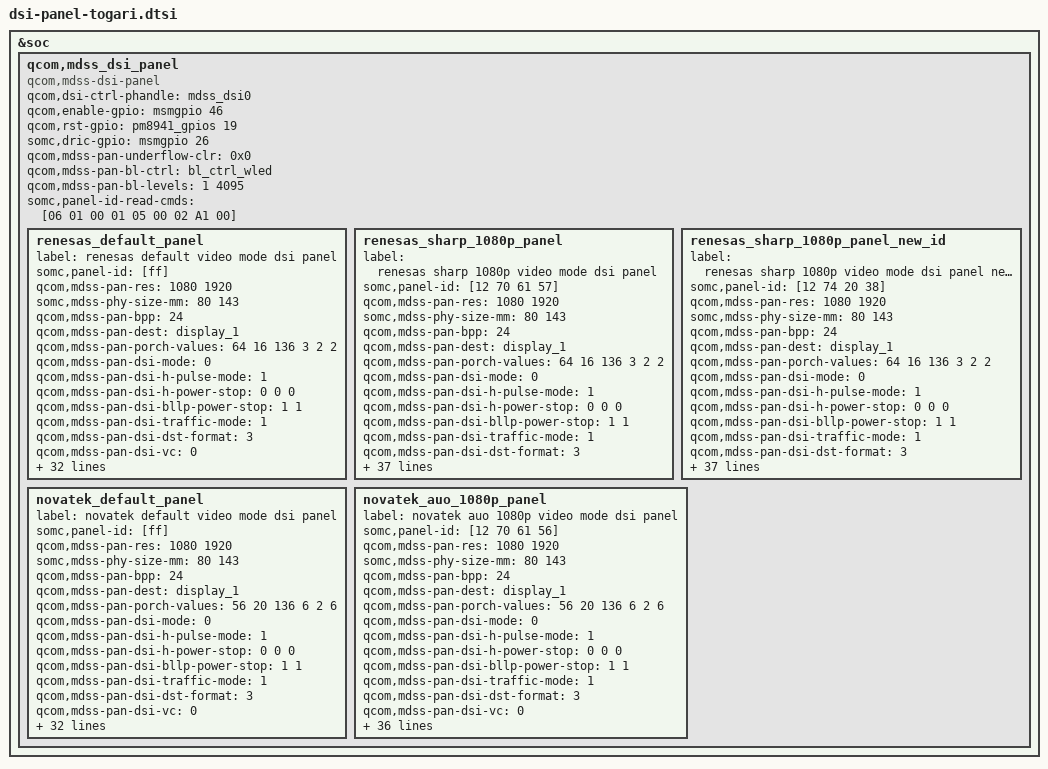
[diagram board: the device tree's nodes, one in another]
/* Copyright (c) 2012, Code Aurora Forum. All rights reserved.
 * Copyright (C) 2012-2013 Sony Mobile Communications AB.
 *
 * This program is free software; you can redistribute it and/or modify
 * it under the terms of the GNU General Public License version 2 and
 * only version 2 as published by the Free Software Foundation.
 *
 * This program is distributed in the hope that it will be useful,
 * but WITHOUT ANY WARRANTY; without even the implied warranty of
 * MERCHANTABILITY or FITNESS FOR A PARTICULAR PURPOSE.  See the
 * GNU General Public License for more details.
 */

&soc {

	qcom,mdss_dsi_panel {
		/* common */
		compatible = "qcom,mdss-dsi-panel";
		status = "ok";
		qcom,dsi-ctrl-phandle = <&mdss_dsi0>;
		qcom,enable-gpio = <&msmgpio 46 0>;
		qcom,rst-gpio = <&pm8941_gpios 19 0>;
		somc,dric-gpio = <&msmgpio 26 0>;
		qcom,mdss-pan-underflow-clr = <0x0>;
		qcom,mdss-pan-bl-ctrl = "bl_ctrl_wled";
		qcom,mdss-pan-bl-levels = <1 4095>;
		somc,panel-id-read-cmds = [06 01 00 01 05 00 02 A1 00];

		renesas_default_panel {
			label = "renesas default video mode dsi panel";
			somc,panel-id = [ff];
			qcom,mdss-pan-res = <1080 1920>;
			somc,mdss-phy-size-mm = <80 143>;
			qcom,mdss-pan-bpp = <24>;
			qcom,mdss-pan-dest = "display_1";
			qcom,mdss-pan-porch-values = <64 16 136 3 2 2>;
			qcom,mdss-pan-dsi-mode = <0>;
			qcom,mdss-pan-dsi-h-pulse-mode = <1>;
			qcom,mdss-pan-dsi-h-power-stop = <0 0 0>;
			qcom,mdss-pan-dsi-bllp-power-stop = <1 1>;
			qcom,mdss-pan-dsi-traffic-mode = <1>;
			qcom,mdss-pan-dsi-dst-format = <3>;
			qcom,mdss-pan-dsi-vc = <0>;
			qcom,mdss-pan-dsi-rgb-swap = <0>;
			qcom,mdss-pan-dsi-data-lanes = <1 1 1 1>;
			qcom,mdss-pan-dsi-dlane-swap = <0>;
			qcom,mdss-pan-dsi-t-clk = <0x31 0x03>;
			qcom,mdss-pan-dsi-stream = <0>;
			qcom,mdss-pan-dsi-mdp-tr = <0x0>;
			qcom,mdss-pan-dsi-dma-tr = <0x04>;
			qcom,mdss-pan-dsi-frame-rate = <60>;
			qcom,panel-phy-regulatorSettings = [07 09 03 00  /* Regualotor settings */
							    20 00 01];
			qcom,panel-phy-timingSettings = [EA 38 25 00 67 6F
							    29 3C 5D 03 04 00];
			qcom,panel-phy-strengthCtrl = [ff 06];
			qcom,panel-phy-bistCtrl = [00 00 b1 ff           /* BIST Ctrl settings */
						   00 00];
			qcom,panel-phy-laneConfig = [00 c2 ef 00 00 00 00 01 75 /* lane0 config */
						00 c2 ef 00 00 00 00 01 75 /* lane1 config */
						00 c2 ef 00 00 00 00 01 75 /* lane2 config */
						00 c2 ef 00 00 00 00 01 75 /* lane3 config */
						00 02 45 00 00 00 00 01 97]; /* Clk ln config */

			somc,panel-cabc-early-on-cmds = [39 01 00 00 00 00 03 51 0F FF
							15 01 00 00 00 00 02 53 24
							15 01 00 00 00 00 02 55 03
							23 01 00 00 00 00 02 B0 00
							29 01 00 00 00 00 08 B9 00 3F 18 18 9F 1F 80
							29 01 00 00 00 00 08 BA 00 3F 04 40 9F 1F A8
							29 01 00 00 00 00 0B B8 18 80 18 18 CF 1F 00 0C 0F 6C
							29 01 00 00 00 00 0F 0F 6C 0F 0C 0F DA 6D FF FF 10 7D BC F7 FF FF
							23 01 00 00 00 00 02 B0 03];
			somc,panel-cabc-late-off-cmds = [39 01 00 00 00 00 03 51 00 00
							15 01 00 00 00 00 02 55 00
							15 01 00 00 00 00 02 53 20];
			somc,cabc-enabled = <1>;
			somc,panel-init-cmds = [29 01 00 00 00 00 02 B0 04
				05 01 00 00 00 00 02 00 00
				05 01 00 00 00 00 02 00 00
				29 01 00 00 00 00 07 B3 14 00 00 00 00 00
				29 01 00 00 00 00 03 B4 0C 00
				29 01 00 00 00 00 03 B6 3A D3
				29 01 00 00 00 00 02 B7 00
				29 01 00 00 00 00 03 BB 00 10
				29 01 00 00 00 00 03 C0 00 00
				29 01 00 00 00 00 23 C1
					04 60 00 40 0C 00 50 02 00 00 00 5C 63 AC 39 00
					00 50 00 00 00 86 00 00 00 00 00 00 40 00 02 02
					02 00
				29 01 00 00 00 00 08 C2 30 17 80 05 08 00 00
				29 01 00 00 00 00 04 C3 00 00 00
				29 01 00 00 00 00 17 C4
					70 00 00 00 00 00 00 00 00 00 06 00 00 00 00 00
					00 00 00 00 00 06
				29 01 00 00 00 00 29 C6
					01 6E 02 67 00 00 00 00 00 00 00 00 00 00 00 00
					04 19 0A 03 C7 01 6E 02 67 00 00 00 00 00 00 00
					00 00 00 00 00 04 19 0A
				29 01 00 00 00 00 19 C7
					0F 14 17 1B 22 42 36 51 62 6B 6E 6E 11 15 19 1D
					24 3F 34 53 65 6D 6F 71
				29 01 00 00 00 00 19 C8
					0F 14 18 1E 29 42 35 50 62 6B 71 73 11 16 1A 20
					2B 40 33 52 64 6C 72 76
				29 01 00 00 00 00 19 C9
					13 17 1B 20 2B 42 35 52 63 6B 6F 6F 15 19 1D 22
					2C 40 34 53 64 6C 70 72
				29 01 00 00 00 00 21 CA
					00 80 80 80 80 80 80 80 08 20 80 80 0A 4A 37 A0
					55 F8 0C 0C 20 10 3F 3F 00 00 10 10 3F 3F 3F 3F
				29 01 00 00 00 00 0A CB 66 E0 87 61 00 00 00 00 C0
				29 01 00 00 00 00 02 CC 03
				29 01 00 00 00 00 08 CE 00 01 00 C1 00 00 00
				29 01 00 00 00 00 06 CF 00 00 C1 05 3F
				29 01 00 00 00 00 0F D0 00 00 19 18 99 9C 1C 01 81 00 BB 1B 0B 01
				29 01 00 00 00 00 1E D1
					20 00 00 04 08 0C 10 00 00 00 00 00 3C 04 20 00
					00 04 08 0C 10 00 00 3C 06 40 00 32 31
				29 01 00 00 00 00 04 D2 5C 00 00
				29 01 00 00 00 00 1B D3
					1B 33 BB CC C4 33 33 33 00 01 00 A0 F8 A0 00 3F
					33 33 22 70 02 37 03 3D BF 99
				29 01 00 00 00 00 15 D7
					84 E0 7F A8 CE 38 FC C1 83 E7 83 1F 3C 10 FA C3
					0F 04 41 20
				29 01 00 00 00 00 07 D8 00 80 80 40 42 21
				29 01 00 00 00 00 03 D9 20 00
				29 01 00 00 00 00 03 DD 10 8C
				29 01 00 00 00 00 07 DE 00 FF 07 10 00 77
				29 01 00 00 00 00 03 EC 40 10
				29 01 00 00 00 00 04 ED 00 00 00
				29 01 00 00 00 00 03 EE 00 32
				29 01 00 00 00 00 0D EF 00 00 00 00 00 00 00 00 00 00 00 00
				29 01 00 00 00 00 02 D6 01
				05 01 00 00 00 00 01 11];
			qcom,panel-on-cmds = [05 01 00 00 00 00 01 29];

			qcom,on-cmds-dsi-state = "DSI_LP_MODE";
			qcom,panel-off-cmds = [05 01 00 00 14 00 01 28
					05 01 00 00 64 00 01 10];
			qcom,off-cmds-dsi-state = "DSI_HS_MODE";
			somc,driver-ic = <0>;
			somc,disp-on-in-hs = <1>;
			somc,panel-detect = <1>;
			somc,wait-time-before-on-cmd = <150>;
		};

		renesas_sharp_1080p_panel {
			label = "renesas sharp 1080p video mode dsi panel";
			somc,panel-id = [12 70 61 57];
			qcom,mdss-pan-res = <1080 1920>;
			somc,mdss-phy-size-mm = <80 143>;
			qcom,mdss-pan-bpp = <24>;
			qcom,mdss-pan-dest = "display_1";
			qcom,mdss-pan-porch-values = <64 16 136 3 2 2>;
			qcom,mdss-pan-dsi-mode = <0>;
			qcom,mdss-pan-dsi-h-pulse-mode = <1>;
			qcom,mdss-pan-dsi-h-power-stop = <0 0 0>;
			qcom,mdss-pan-dsi-bllp-power-stop = <1 1>;
			qcom,mdss-pan-dsi-traffic-mode = <1>;
			qcom,mdss-pan-dsi-dst-format = <3>;
			qcom,mdss-pan-dsi-vc = <0>;
			qcom,mdss-pan-dsi-rgb-swap = <0>;
			qcom,mdss-pan-dsi-data-lanes = <1 1 1 1>;
			qcom,mdss-pan-dsi-dlane-swap = <0>;
			qcom,mdss-pan-dsi-t-clk = <0x31 0x03>;
			qcom,mdss-pan-dsi-stream = <0>;
			qcom,mdss-pan-dsi-mdp-tr = <0x0>;
			qcom,mdss-pan-dsi-dma-tr = <0x04>;
			qcom,mdss-pan-dsi-frame-rate = <60>;
			qcom,panel-phy-regulatorSettings = [07 09 03 00  /* Regualotor settings */
							    20 00 01];
			qcom,panel-phy-timingSettings = [EA 38 25 00 67 6F
							    29 3C 5D 03 04 00];
			qcom,panel-phy-strengthCtrl = [ff 06];
			qcom,panel-phy-bistCtrl = [00 00 b1 ff           /* BIST Ctrl settings */
						   00 00];
			qcom,panel-phy-laneConfig = [00 c2 ef 00 00 00 00 01 75 /* lane0 config */
						00 c2 ef 00 00 00 00 01 75 /* lane1 config */
						00 c2 ef 00 00 00 00 01 75 /* lane2 config */
						00 c2 ef 00 00 00 00 01 75 /* lane3 config */
						00 02 45 00 00 00 00 01 97]; /* Clk ln config */

			somc,panel-cabc-early-on-cmds = [39 01 00 00 00 00 03 51 0F FF
							15 01 00 00 00 00 02 53 24
							15 01 00 00 00 00 02 55 03
							23 01 00 00 00 00 02 B0 00
							29 01 00 00 00 00 08 B9 00 3F 18 18 9F 1F 80
							29 01 00 00 00 00 08 BA 00 3F 04 40 9F 1F A8
							29 01 00 00 00 00 0B B8 18 80 18 18 CF 1F 00 0C 0F 6C
							29 01 00 00 00 00 0F 0F 6C 0F 0C 0F DA 6D FF FF 10 7D BC F7 FF FF
							23 01 00 00 00 00 02 B0 03];
			somc,panel-cabc-late-off-cmds = [39 01 00 00 00 00 03 51 00 00
							15 01 00 00 00 00 02 55 00
							15 01 00 00 00 00 02 53 20];
			somc,cabc-enabled = <1>;

			somc,panel-init-cmds = [29 01 00 00 00 00 02 B0 04
				05 01 00 00 00 00 02 00 00
				05 01 00 00 00 00 02 00 00
				29 01 00 00 00 00 07 B3 14 00 00 00 00 00
				29 01 00 00 00 00 03 B4 0C 00
				29 01 00 00 00 00 03 B6 3A D3
				29 01 00 00 00 00 02 B7 00
				29 01 00 00 00 00 03 BB 00 10
				29 01 00 00 00 00 03 C0 00 00
				29 01 00 00 00 00 23 C1
					04 60 00 40 0C 00 50 02 00 00 00 5C 63 AC 39 00
					00 50 00 00 00 86 00 00 00 00 00 00 40 00 02 02
					02 00
				29 01 00 00 00 00 08 C2 30 17 80 05 08 00 00
				29 01 00 00 00 00 04 C3 00 00 00
				29 01 00 00 00 00 17 C4
					70 00 00 00 00 00 00 00 00 00 06 00 00 00 00 00
					00 00 00 00 00 06
				29 01 00 00 00 00 29 C6
					01 6E 02 67 00 00 00 00 00 00 00 00 00 00 00 00
					04 19 0A 03 C7 01 6E 02 67 00 00 00 00 00 00 00
					00 00 00 00 00 04 19 0A
				29 01 00 00 00 00 19 C7
					0F 14 17 1B 22 42 36 51 62 6B 6E 6E 11 15 19 1D
					24 3F 34 53 65 6D 6F 71
				29 01 00 00 00 00 19 C8
					0F 14 18 1E 29 42 35 50 62 6B 71 73 11 16 1A 20
					2B 40 33 52 64 6C 72 76
				29 01 00 00 00 00 19 C9
					13 17 1B 20 2B 42 35 52 63 6B 6F 6F 15 19 1D 22
					2C 40 34 53 64 6C 70 72
				29 01 00 00 00 00 21 CA
					00 80 80 80 80 80 80 80 08 20 80 80 0A 4A 37 A0
					55 F8 0C 0C 20 10 3F 3F 00 00 10 10 3F 3F 3F 3F
				29 01 00 00 00 00 0A CB 66 E0 87 61 00 00 00 00 C0
				29 01 00 00 00 00 02 CC 03
				29 01 00 00 00 00 08 CE 00 01 00 C1 00 00 00
				29 01 00 00 00 00 06 CF 00 00 C1 05 3F
				29 01 00 00 00 00 0F D0 00 00 19 18 99 9C 1C 01 81 00 BB 1B 0B 01
				29 01 00 00 00 00 1E D1
					20 00 00 04 08 0C 10 00 00 00 00 00 3C 04 20 00
					00 04 08 0C 10 00 00 3C 06 40 00 32 31
				29 01 00 00 00 00 04 D2 5C 00 00
				29 01 00 00 00 00 1B D3
					1B 33 BB CC C4 33 33 33 00 01 00 A0 F8 A0 00 3F
					33 33 22 70 02 37 03 3D BF 99
				29 01 00 00 00 00 15 D7
					84 E0 7F A8 CE 38 FC C1 83 E7 83 1F 3C 10 FA C3
					0F 04 41 20
				29 01 00 00 00 00 07 D8 00 80 80 40 42 21
				29 01 00 00 00 00 03 D9 20 00
				29 01 00 00 00 00 03 DD 10 8C
				29 01 00 00 00 00 07 DE 00 FF 07 10 00 77
				29 01 00 00 00 00 03 EC 40 10
				29 01 00 00 00 00 04 ED 00 00 00
				29 01 00 00 00 00 03 EE 00 32
				29 01 00 00 00 00 0D EF 00 00 00 00 00 00 00 00 00 00 00 00
				29 01 00 00 00 00 02 D6 01
				05 01 00 00 00 00 01 11];
			qcom,panel-on-cmds = [05 01 00 00 00 00 01 29];

			qcom,on-cmds-dsi-state = "DSI_LP_MODE";
			qcom,panel-off-cmds = [05 01 00 00 14 00 01 28
					05 01 00 00 64 00 01 10];
			qcom,off-cmds-dsi-state = "DSI_HS_MODE";
			somc,driver-ic = <0>;
			somc,disp-on-in-hs = <1>;
			somc,wait-time-before-on-cmd = <150>;

			somc,panel-uv-cmds = [04 01 00 00 00 00 01 EF];
			somc,panel-pcc-table = <0x07c00 0x05f80 0x07380	/* CLR01_GRN */
					0x05100 0x06600 0x07380		/* CLR02_YEL */
					0x07d80 0x05f80 0x06300		/* CLR03_LB */
					0x04e00 0x06600 0x06100		/* CLR04_ORG */
					0x07d00 0x05f00 0x05680		/* CLR05_BLE */
					0x07d80 0x08000 0x06f80		/* CLR06_PUR */
					0x04d00 0x06600 0x05280>;	/* CLR07_RED */
			somc,panel-pcc-sub-table = <0x06800 0x06f80 0x08000 /* Area01 (R G B) */
					0x06500 0x07100 0x08000
					0x07600 0x07400 0x08000
					0x07480 0x07580 0x08000
					0x07280 0x07500 0x08000
					0x06d80 0x07500 0x08000
					0x06780 0x07300 0x08000
					0x07a00 0x07680 0x08000
					0x07900 0x07800 0x08000
					0x07180 0x07800 0x08000
					0x06f00 0x07880 0x08000
					0x06c00 0x07800 0x08000
					0x07d80 0x07980 0x08000
					0x07b80 0x07b00 0x08000
					0x07600 0x07d00 0x08000
					0x07180 0x07b00 0x08000
					0x07000 0x07d00 0x08000
					0x08000 0x07980 0x07d00
					0x07f00 0x07b00 0x07d80
					0x07c00 0x07c00 0x07c80
					0x07100 0x07b00 0x07d00
					0x07280 0x07d00 0x07e80
					0x07000 0x07d00 0x07e80
					0x08000 0x07800 0x07900
					0x08000 0x07c00 0x07c00
					0x07a80 0x08000 0x07e80
					0x07680 0x08000 0x07d80
					0x07300 0x08000 0x07f00
					0x08000 0x07800 0x07580
					0x08000 0x07b00 0x07780
					0x08000 0x08000 0x07c80
					0x07900 0x08000 0x07980
					0x08000 0x07880 0x07480
					0x08000 0x07c00 0x07600
					0x07d80 0x08000 0x07880
					0x07300 0x08000 0x07780
					0x08000 0x07400 0x07c80
					0x07880 0x06e00 0x08000
					0x06b80 0x06b00 0x07e00
					0x06080 0x05f80 0x07780
					0x05880 0x06500 0x07c80
					0x05500 0x06600 0x05e80>;
		};

		renesas_sharp_1080p_panel_new_id {
			label = "renesas sharp 1080p video mode dsi panel new id";
			somc,panel-id = [12 74 20 38];
			qcom,mdss-pan-res = <1080 1920>;
			somc,mdss-phy-size-mm = <80 143>;
			qcom,mdss-pan-bpp = <24>;
			qcom,mdss-pan-dest = "display_1";
			qcom,mdss-pan-porch-values = <64 16 136 3 2 2>;
			qcom,mdss-pan-dsi-mode = <0>;
			qcom,mdss-pan-dsi-h-pulse-mode = <1>;
			qcom,mdss-pan-dsi-h-power-stop = <0 0 0>;
			qcom,mdss-pan-dsi-bllp-power-stop = <1 1>;
			qcom,mdss-pan-dsi-traffic-mode = <1>;
			qcom,mdss-pan-dsi-dst-format = <3>;
			qcom,mdss-pan-dsi-vc = <0>;
			qcom,mdss-pan-dsi-rgb-swap = <0>;
			qcom,mdss-pan-dsi-data-lanes = <1 1 1 1>;
			qcom,mdss-pan-dsi-dlane-swap = <0>;
			qcom,mdss-pan-dsi-t-clk = <0x31 0x03>;
			qcom,mdss-pan-dsi-stream = <0>;
			qcom,mdss-pan-dsi-mdp-tr = <0x0>;
			qcom,mdss-pan-dsi-dma-tr = <0x04>;
			qcom,mdss-pan-dsi-frame-rate = <60>;
			qcom,panel-phy-regulatorSettings = [07 09 03 00  /* Regualotor settings */
							    20 00 01];
			qcom,panel-phy-timingSettings = [EA 38 25 00 67 6F
							    29 3C 5D 03 04 00];
			qcom,panel-phy-strengthCtrl = [ff 06];
			qcom,panel-phy-bistCtrl = [00 00 b1 ff           /* BIST Ctrl settings */
						   00 00];
			qcom,panel-phy-laneConfig = [00 c2 ef 00 00 00 00 01 75 /* lane0 config */
						00 c2 ef 00 00 00 00 01 75 /* lane1 config */
						00 c2 ef 00 00 00 00 01 75 /* lane2 config */
						00 c2 ef 00 00 00 00 01 75 /* lane3 config */
						00 02 45 00 00 00 00 01 97]; /* Clk ln config */

			somc,panel-cabc-early-on-cmds = [39 01 00 00 00 00 03 51 0F FF
							15 01 00 00 00 00 02 53 24
							15 01 00 00 00 00 02 55 03
							23 01 00 00 00 00 02 B0 00
							29 01 00 00 00 00 08 B9 00 3F 18 18 9F 1F 80
							29 01 00 00 00 00 08 BA 00 3F 04 40 9F 1F A8
							29 01 00 00 00 00 0B B8 18 80 18 18 CF 1F 00 0C 0F 6C
							29 01 00 00 00 00 0F 0F 6C 0F 0C 0F DA 6D FF FF 10 7D BC F7 FF FF
							23 01 00 00 00 00 02 B0 03];
			somc,panel-cabc-late-off-cmds = [39 01 00 00 00 00 03 51 00 00
							15 01 00 00 00 00 02 55 00
							15 01 00 00 00 00 02 53 20];
			somc,cabc-enabled = <1>;

			somc,panel-init-cmds = [29 01 00 00 00 00 02 B0 04
				05 01 00 00 00 00 02 00 00
				05 01 00 00 00 00 02 00 00
				29 01 00 00 00 00 07 B3 14 00 00 00 00 00
				29 01 00 00 00 00 03 B4 0C 00
				29 01 00 00 00 00 03 B6 3A D3
				29 01 00 00 00 00 02 B7 00
				29 01 00 00 00 00 03 BB 00 10
				29 01 00 00 00 00 03 C0 00 00
				29 01 00 00 00 00 23 C1
					04 60 00 40 0C 00 50 02 00 00 00 5C 63 AC 39 00
					00 50 00 00 00 86 00 00 00 00 00 00 40 00 02 02
					02 00
				29 01 00 00 00 00 08 C2 30 17 80 05 08 00 00
				29 01 00 00 00 00 04 C3 00 00 00
				29 01 00 00 00 00 17 C4
					70 00 00 00 00 00 00 00 00 00 06 00 00 00 00 00
					00 00 00 00 00 06
				29 01 00 00 00 00 29 C6
					01 6E 02 67 00 00 00 00 00 00 00 00 00 00 00 00
					04 19 0A 03 C7 01 6E 02 67 00 00 00 00 00 00 00
					00 00 00 00 00 04 19 0A
				29 01 00 00 00 00 19 C7
					0F 14 17 1B 22 42 36 51 62 6B 6E 6E 11 15 19 1D
					24 3F 34 53 65 6D 6F 71
				29 01 00 00 00 00 19 C8
					0F 14 18 1E 29 42 35 50 62 6B 71 73 11 16 1A 20
					2B 40 33 52 64 6C 72 76
				29 01 00 00 00 00 19 C9
					13 17 1B 20 2B 42 35 52 63 6B 6F 6F 15 19 1D 22
					2C 40 34 53 64 6C 70 72
				29 01 00 00 00 00 21 CA
					00 80 80 80 80 80 80 80 08 20 80 80 0A 4A 37 A0
					55 F8 0C 0C 20 10 3F 3F 00 00 10 10 3F 3F 3F 3F
				29 01 00 00 00 00 0A CB 66 E0 87 61 00 00 00 00 C0
				29 01 00 00 00 00 02 CC 03
				29 01 00 00 00 00 08 CE 00 01 00 C1 00 00 00
				29 01 00 00 00 00 06 CF 00 00 C1 05 3F
				29 01 00 00 00 00 0F D0 00 00 19 18 99 9C 1C 01 81 00 BB 1B 0B 01
				29 01 00 00 00 00 1E D1
					20 00 00 04 08 0C 10 00 00 00 00 00 3C 04 20 00
					00 04 08 0C 10 00 00 3C 06 40 00 32 31
				29 01 00 00 00 00 04 D2 5C 00 00
				29 01 00 00 00 00 1B D3
					1B 33 BB CC C4 33 33 33 00 01 00 A0 F8 A0 00 3F
					33 33 22 70 02 37 03 3D BF 99
				29 01 00 00 00 00 15 D7
					84 E0 7F A8 CE 38 FC C1 83 E7 83 1F 3C 10 FA C3
					0F 04 41 20
				29 01 00 00 00 00 07 D8 00 80 80 40 42 21
				29 01 00 00 00 00 03 D9 20 00
				29 01 00 00 00 00 03 DD 10 8C
				29 01 00 00 00 00 07 DE 00 FF 07 10 00 77
				29 01 00 00 00 00 03 EC 40 10
				29 01 00 00 00 00 04 ED 00 00 00
				29 01 00 00 00 00 03 EE 00 32
				29 01 00 00 00 00 0D EF 00 00 00 00 00 00 00 00 00 00 00 00
				29 01 00 00 00 00 02 D6 01
				05 01 00 00 00 00 01 11];
			qcom,panel-on-cmds = [05 01 00 00 00 00 01 29];

			qcom,on-cmds-dsi-state = "DSI_LP_MODE";
			qcom,panel-off-cmds = [05 01 00 00 14 00 01 28
					05 01 00 00 64 00 01 10];
			qcom,off-cmds-dsi-state = "DSI_HS_MODE";
			somc,driver-ic = <0>;
			somc,disp-on-in-hs = <1>;
			somc,wait-time-before-on-cmd = <150>;

			somc,panel-uv-cmds = [04 01 00 00 00 00 01 EF];
			somc,panel-pcc-table = <0x07c00 0x05f80 0x07380	/* CLR01_GRN */
					0x05100 0x06600 0x07380		/* CLR02_YEL */
					0x07d80 0x05f80 0x06300		/* CLR03_LB */
					0x04e00 0x06600 0x06100		/* CLR04_ORG */
					0x07d00 0x05f00 0x05680		/* CLR05_BLE */
					0x07d80 0x08000 0x06f80		/* CLR06_PUR */
					0x04d00 0x06600 0x05280>;	/* CLR07_RED */
			somc,panel-pcc-sub-table = <0x06800 0x06f80 0x08000 /* Area01 (R G B) */
					0x06500 0x07100 0x08000
					0x07600 0x07400 0x08000
					0x07480 0x07580 0x08000
					0x07280 0x07500 0x08000
					0x06d80 0x07500 0x08000
					0x06780 0x07300 0x08000
					0x07a00 0x07680 0x08000
					0x07900 0x07800 0x08000
					0x07180 0x07800 0x08000
					0x06f00 0x07880 0x08000
					0x06c00 0x07800 0x08000
					0x07d80 0x07980 0x08000
					0x07b80 0x07b00 0x08000
					0x07600 0x07d00 0x08000
					0x07180 0x07b00 0x08000
					0x07000 0x07d00 0x08000
					0x08000 0x07980 0x07d00
					0x07f00 0x07b00 0x07d80
					0x07c00 0x07c00 0x07c80
					0x07100 0x07b00 0x07d00
					0x07280 0x07d00 0x07e80
					0x07000 0x07d00 0x07e80
					0x08000 0x07800 0x07900
					0x08000 0x07c00 0x07c00
					0x07a80 0x08000 0x07e80
					0x07680 0x08000 0x07d80
					0x07300 0x08000 0x07f00
					0x08000 0x07800 0x07580
					0x08000 0x07b00 0x07780
					0x08000 0x08000 0x07c80
					0x07900 0x08000 0x07980
					0x08000 0x07880 0x07480
					0x08000 0x07c00 0x07600
					0x07d80 0x08000 0x07880
					0x07300 0x08000 0x07780
					0x08000 0x07400 0x07c80
					0x07880 0x06e00 0x08000
					0x06b80 0x06b00 0x07e00
					0x06080 0x05f80 0x07780
					0x05880 0x06500 0x07c80
					0x05500 0x06600 0x05e80>;
		};

		novatek_default_panel {
			label = "novatek default video mode dsi panel";
			somc,panel-id = [ff];
			qcom,mdss-pan-res = <1080 1920>;
			somc,mdss-phy-size-mm = <80 143>;
			qcom,mdss-pan-bpp = <24>;
			qcom,mdss-pan-dest = "display_1";
			qcom,mdss-pan-porch-values = <56 20 136 6 2 6>;
			qcom,mdss-pan-dsi-mode = <0>;
			qcom,mdss-pan-dsi-h-pulse-mode = <1>;
			qcom,mdss-pan-dsi-h-power-stop = <0 0 0>;
			qcom,mdss-pan-dsi-bllp-power-stop = <1 1>;
			qcom,mdss-pan-dsi-traffic-mode = <1>;
			qcom,mdss-pan-dsi-dst-format = <3>;
			qcom,mdss-pan-dsi-vc = <0>;
			qcom,mdss-pan-dsi-rgb-swap = <0>;
			qcom,mdss-pan-dsi-data-lanes = <1 1 1 1>;
			qcom,mdss-pan-dsi-dlane-swap = <0>;
			qcom,mdss-pan-dsi-t-clk = <0x37 0x1E>;
			qcom,mdss-pan-dsi-stream = <0>;
			qcom,mdss-pan-dsi-mdp-tr = <0x0>;
			qcom,mdss-pan-dsi-dma-tr = <0x04>;
			qcom,mdss-pan-dsi-frame-rate = <60>;
			qcom,panel-phy-regulatorSettings = [07 09 03 00  /* Regualotor settings */
							    20 00 01];
			qcom,panel-phy-timingSettings = [DA 46 39 00 5F 56
							    3C 48 5D 03 04 00];
			qcom,panel-phy-strengthCtrl = [ff 06];
			qcom,panel-phy-bistCtrl = [00 00 b1 ff           /* BIST Ctrl settings */
						   00 00];
			qcom,panel-phy-laneConfig = [00 02 ef 00 00 00 00 01 ff /* lane0 config */
						00 02 ef 00 00 00 00 01 ff /* lane1 config */
						00 02 ef 00 00 00 00 01 ff /* lane2 config */
						00 02 ef 00 00 00 00 01 ff /* lane3 config */
						00 02 45 00 00 00 00 01 97]; /* Clk ln config */

			somc,panel-cabc-early-on-cmds = [15 01 00 00 00 00 02 FF 04
						15 01 00 00 00 00 02 08 05
						15 01 00 00 00 00 02 2A 84
						15 01 00 00 00 00 02 29 99
						15 01 00 00 00 00 02 28 99
						15 01 00 00 00 00 02 27 99
						15 01 00 00 00 00 02 26 AA
						15 01 00 00 00 00 02 25 BB
						15 01 00 00 00 00 02 24 CC
						15 01 00 00 00 00 02 23 DD
						15 01 00 00 00 00 02 22 EE
						15 01 00 00 00 00 02 21 FF
						15 01 00 00 00 00 02 33 0C
						15 01 00 00 00 00 02 FB 01
						15 01 00 00 00 00 02 FF 00
						15 01 00 00 00 00 02 51 FF
						15 01 00 00 00 00 02 53 2C
						15 01 00 00 00 00 02 55 03];
			somc,panel-cabc-late-off-cmds = [15 01 00 00 00 00 02 51 00
						15 01 00 00 00 00 02 53 00
						15 01 00 00 00 00 02 55 00];
			somc,cabc-enabled = <1>;
			somc,panel-init-cmds = [15 01 00 00 00 00 02 FF 01
					15 01 00 00 00 00 02 FB 01
					15 01 00 00 00 00 02 75 00
					15 01 00 00 00 00 02 76 16
					15 01 00 00 00 00 02 77 00
					15 01 00 00 00 00 02 78 2D
					15 01 00 00 00 00 02 79 00
					15 01 00 00 00 00 02 7A 54
					15 01 00 00 00 00 02 7B 00
					15 01 00 00 00 00 02 7C 70
					15 01 00 00 00 00 02 7D 00
					15 01 00 00 00 00 02 7E 87
					15 01 00 00 00 00 02 7F 00
					15 01 00 00 00 00 02 80 9A
					15 01 00 00 00 00 02 81 00
					15 01 00 00 00 00 02 82 AB
					15 01 00 00 00 00 02 83 00
					15 01 00 00 00 00 02 84 BA
					15 01 00 00 00 00 02 85 00
					15 01 00 00 00 00 02 86 C8
					15 01 00 00 00 00 02 87 00
					15 01 00 00 00 00 02 88 F6
					15 01 00 00 00 00 02 89 01
					15 01 00 00 00 00 02 8A 1A
					15 01 00 00 00 00 02 8B 01
					15 01 00 00 00 00 02 8C 53
					15 01 00 00 00 00 02 8D 01
					15 01 00 00 00 00 02 8E 80
					15 01 00 00 00 00 02 8F 01
					15 01 00 00 00 00 02 90 C7
					15 01 00 00 00 00 02 91 02
					15 01 00 00 00 00 02 92 01
					15 01 00 00 00 00 02 93 02
					15 01 00 00 00 00 02 94 02
					15 01 00 00 00 00 02 95 02
					15 01 00 00 00 00 02 96 39
					15 01 00 00 00 00 02 97 02
					15 01 00 00 00 00 02 98 7D
					15 01 00 00 00 00 02 99 02
					15 01 00 00 00 00 02 9A AB
					15 01 00 00 00 00 02 9B 02
					15 01 00 00 00 00 02 9C E8
					15 01 00 00 00 00 02 9D 03
					15 01 00 00 00 00 02 9E 12
					15 01 00 00 00 00 02 9F 03
					15 01 00 00 00 00 02 A0 49
					15 01 00 00 00 00 02 A2 03
					15 01 00 00 00 00 02 A3 5C
					15 01 00 00 00 00 02 A4 03
					15 01 00 00 00 00 02 A5 72
					15 01 00 00 00 00 02 A6 03
					15 01 00 00 00 00 02 A7 83
					15 01 00 00 00 00 02 A9 03
					15 01 00 00 00 00 02 AA 97
					15 01 00 00 00 00 02 AB 03
					15 01 00 00 00 00 02 AC A4
					15 01 00 00 00 00 02 AD 03
					15 01 00 00 00 00 02 AE B6
					15 01 00 00 00 00 02 AF 03
					15 01 00 00 00 00 02 B0 C8
					15 01 00 00 00 00 02 B1 03
					15 01 00 00 00 00 02 B2 CB
					15 01 00 00 00 00 02 B3 00
					15 01 00 00 00 00 02 B4 16
					15 01 00 00 00 00 02 B5 00
					15 01 00 00 00 00 02 B6 2D
					15 01 00 00 00 00 02 B7 00
					15 01 00 00 00 00 02 B8 54
					15 01 00 00 00 00 02 B9 00
					15 01 00 00 00 00 02 BA 70
					15 01 00 00 00 00 02 BB 00
					15 01 00 00 00 00 02 BC 87
					15 01 00 00 00 00 02 BD 00
					15 01 00 00 00 00 02 BE 9A
					15 01 00 00 00 00 02 BF 00
					15 01 00 00 00 00 02 C0 AB
					15 01 00 00 00 00 02 C1 00
					15 01 00 00 00 00 02 C2 BA
					15 01 00 00 00 00 02 C3 00
					15 01 00 00 00 00 02 C4 C8
					15 01 00 00 00 00 02 C5 00
					15 01 00 00 00 00 02 C6 F6
					15 01 00 00 00 00 02 C7 01
					15 01 00 00 00 00 02 C8 1A
					15 01 00 00 00 00 02 C9 01
					15 01 00 00 00 00 02 CA 53
					15 01 00 00 00 00 02 CB 01
					15 01 00 00 00 00 02 CC 80
					15 01 00 00 00 00 02 CD 01
					15 01 00 00 00 00 02 CE C7
					15 01 00 00 00 00 02 CF 02
					15 01 00 00 00 00 02 D0 01
					15 01 00 00 00 00 02 D1 02
					15 01 00 00 00 00 02 D2 02
					15 01 00 00 00 00 02 D3 02
					15 01 00 00 00 00 02 D4 39
					15 01 00 00 00 00 02 D5 02
					15 01 00 00 00 00 02 D6 7D
					15 01 00 00 00 00 02 D7 02
					15 01 00 00 00 00 02 D8 AB
					15 01 00 00 00 00 02 D9 02
					15 01 00 00 00 00 02 DA E8
					15 01 00 00 00 00 02 DB 03
					15 01 00 00 00 00 02 DC 12
					15 01 00 00 00 00 02 DD 03
					15 01 00 00 00 00 02 DE 49
					15 01 00 00 00 00 02 DF 03
					15 01 00 00 00 00 02 E0 5C
					15 01 00 00 00 00 02 E1 03
					15 01 00 00 00 00 02 E2 72
					15 01 00 00 00 00 02 E3 03
					15 01 00 00 00 00 02 E4 83
					15 01 00 00 00 00 02 E5 03
					15 01 00 00 00 00 02 E6 97
					15 01 00 00 00 00 02 E7 03
					15 01 00 00 00 00 02 E8 A4
					15 01 00 00 00 00 02 E9 03
					15 01 00 00 00 00 02 EA B6
					15 01 00 00 00 00 02 EB 03
					15 01 00 00 00 00 02 EC C8
					15 01 00 00 00 00 02 ED 03
					15 01 00 00 00 00 02 EE CB
					15 01 00 00 00 00 02 EF 00
					15 01 00 00 00 00 02 F0 16
					15 01 00 00 00 00 02 F1 00
					15 01 00 00 00 00 02 F2 2D
					15 01 00 00 00 00 02 F3 00
					15 01 00 00 00 00 02 F4 54
					15 01 00 00 00 00 02 F5 00
					15 01 00 00 00 00 02 F6 70
					15 01 00 00 00 00 02 F7 00
					15 01 00 00 00 00 02 F8 87
					15 01 00 00 00 00 02 F9 00
					15 01 00 00 00 00 02 FA 9A
					15 01 00 00 00 00 02 FF 02
					15 01 00 00 00 00 02 FB 01
					15 01 00 00 00 00 02 00 00
					15 01 00 00 00 00 02 01 AB
					15 01 00 00 00 00 02 02 00
					15 01 00 00 00 00 02 03 BA
					15 01 00 00 00 00 02 04 00
					15 01 00 00 00 00 02 05 C8
					15 01 00 00 00 00 02 06 00
					15 01 00 00 00 00 02 07 F6
					15 01 00 00 00 00 02 08 01
					15 01 00 00 00 00 02 09 1A
					15 01 00 00 00 00 02 0A 01
					15 01 00 00 00 00 02 0B 53
					15 01 00 00 00 00 02 0C 01
					15 01 00 00 00 00 02 0D 80
					15 01 00 00 00 00 02 0E 01
					15 01 00 00 00 00 02 0F C7
					15 01 00 00 00 00 02 10 02
					15 01 00 00 00 00 02 11 01
					15 01 00 00 00 00 02 12 02
					15 01 00 00 00 00 02 13 02
					15 01 00 00 00 00 02 14 02
					15 01 00 00 00 00 02 15 39
					15 01 00 00 00 00 02 16 02
					15 01 00 00 00 00 02 17 7D
					15 01 00 00 00 00 02 18 02
					15 01 00 00 00 00 02 19 AB
					15 01 00 00 00 00 02 1A 02
					15 01 00 00 00 00 02 1B E8
					15 01 00 00 00 00 02 1C 03
					15 01 00 00 00 00 02 1D 12
					15 01 00 00 00 00 02 1E 03
					15 01 00 00 00 00 02 1F 49
					15 01 00 00 00 00 02 20 03
					15 01 00 00 00 00 02 21 5C
					15 01 00 00 00 00 02 22 03
					15 01 00 00 00 00 02 23 72
					15 01 00 00 00 00 02 24 03
					15 01 00 00 00 00 02 25 83
					15 01 00 00 00 00 02 26 03
					15 01 00 00 00 00 02 27 97
					15 01 00 00 00 00 02 28 03
					15 01 00 00 00 00 02 29 A4
					15 01 00 00 00 00 02 2A 03
					15 01 00 00 00 00 02 2B B6
					15 01 00 00 00 00 02 2D 03
					15 01 00 00 00 00 02 2F C8
					15 01 00 00 00 00 02 30 03
					15 01 00 00 00 00 02 31 CB
					15 01 00 00 00 00 02 32 00
					15 01 00 00 00 00 02 33 16
					15 01 00 00 00 00 02 34 00
					15 01 00 00 00 00 02 35 2D
					15 01 00 00 00 00 02 36 00
					15 01 00 00 00 00 02 37 54
					15 01 00 00 00 00 02 38 00
					15 01 00 00 00 00 02 39 70
					15 01 00 00 00 00 02 3A 00
					15 01 00 00 00 00 02 3B 87
					15 01 00 00 00 00 02 3D 00
					15 01 00 00 00 00 02 3F 9A
					15 01 00 00 00 00 02 40 00
					15 01 00 00 00 00 02 41 AB
					15 01 00 00 00 00 02 42 00
					15 01 00 00 00 00 02 43 BA
					15 01 00 00 00 00 02 44 00
					15 01 00 00 00 00 02 45 C8
					15 01 00 00 00 00 02 46 00
					15 01 00 00 00 00 02 47 F6
					15 01 00 00 00 00 02 48 01
					15 01 00 00 00 00 02 49 1A
					15 01 00 00 00 00 02 4A 01
					15 01 00 00 00 00 02 4B 53
					15 01 00 00 00 00 02 4C 01
					15 01 00 00 00 00 02 4D 80
					15 01 00 00 00 00 02 4E 01
					15 01 00 00 00 00 02 4F C7
					15 01 00 00 00 00 02 50 02
					15 01 00 00 00 00 02 51 01
					15 01 00 00 00 00 02 52 02
					15 01 00 00 00 00 02 53 02
					15 01 00 00 00 00 02 54 02
					15 01 00 00 00 00 02 55 39
					15 01 00 00 00 00 02 56 02
					15 01 00 00 00 00 02 58 7D
					15 01 00 00 00 00 02 59 02
					15 01 00 00 00 00 02 5A AB
					15 01 00 00 00 00 02 5B 02
					15 01 00 00 00 00 02 5C E8
					15 01 00 00 00 00 02 5D 03
					15 01 00 00 00 00 02 5E 12
					15 01 00 00 00 00 02 5F 03
					15 01 00 00 00 00 02 60 49
					15 01 00 00 00 00 02 61 03
					15 01 00 00 00 00 02 62 5C
					15 01 00 00 00 00 02 63 03
					15 01 00 00 00 00 02 64 72
					15 01 00 00 00 00 02 65 03
					15 01 00 00 00 00 02 66 83
					15 01 00 00 00 00 02 67 03
					15 01 00 00 00 00 02 68 97
					15 01 00 00 00 00 02 69 03
					15 01 00 00 00 00 02 6A A4
					15 01 00 00 00 00 02 6B 03
					15 01 00 00 00 00 02 6C B6
					15 01 00 00 00 00 02 6D 03
					15 01 00 00 00 00 02 6E C8
					15 01 00 00 00 00 02 6F 03
					15 01 00 00 00 00 02 70 CB
					15 01 00 00 00 00 02 71 00
					15 01 00 00 00 00 02 72 16
					15 01 00 00 00 00 02 73 00
					15 01 00 00 00 00 02 74 2D
					15 01 00 00 00 00 02 75 00
					15 01 00 00 00 00 02 76 54
					15 01 00 00 00 00 02 77 00
					15 01 00 00 00 00 02 78 70
					15 01 00 00 00 00 02 79 00
					15 01 00 00 00 00 02 7A 87
					15 01 00 00 00 00 02 7B 00
					15 01 00 00 00 00 02 7C 9A
					15 01 00 00 00 00 02 7D 00
					15 01 00 00 00 00 02 7E AB
					15 01 00 00 00 00 02 7F 00
					15 01 00 00 00 00 02 80 BA
					15 01 00 00 00 00 02 81 00
					15 01 00 00 00 00 02 82 C8
					15 01 00 00 00 00 02 83 00
					15 01 00 00 00 00 02 84 F6
					15 01 00 00 00 00 02 85 01
					15 01 00 00 00 00 02 86 1A
					15 01 00 00 00 00 02 87 01
					15 01 00 00 00 00 02 88 53
					15 01 00 00 00 00 02 89 01
					15 01 00 00 00 00 02 8A 80
					15 01 00 00 00 00 02 8B 01
					15 01 00 00 00 00 02 8C C7
					15 01 00 00 00 00 02 8D 02
					15 01 00 00 00 00 02 8E 01
					15 01 00 00 00 00 02 8F 02
					15 01 00 00 00 00 02 90 02
					15 01 00 00 00 00 02 91 02
					15 01 00 00 00 00 02 92 39
					15 01 00 00 00 00 02 93 02
					15 01 00 00 00 00 02 94 7D
					15 01 00 00 00 00 02 95 02
					15 01 00 00 00 00 02 96 AB
					15 01 00 00 00 00 02 97 02
					15 01 00 00 00 00 02 98 E8
					15 01 00 00 00 00 02 99 03
					15 01 00 00 00 00 02 9A 12
					15 01 00 00 00 00 02 9B 03
					15 01 00 00 00 00 02 9C 49
					15 01 00 00 00 00 02 9D 03
					15 01 00 00 00 00 02 9E 5C
					15 01 00 00 00 00 02 9F 03
					15 01 00 00 00 00 02 A0 72
					15 01 00 00 00 00 02 A2 03
					15 01 00 00 00 00 02 A3 83
					15 01 00 00 00 00 02 A4 03
					15 01 00 00 00 00 02 A5 97
					15 01 00 00 00 00 02 A6 03
					15 01 00 00 00 00 02 A7 A4
					15 01 00 00 00 00 02 A9 03
					15 01 00 00 00 00 02 AA B6
					15 01 00 00 00 00 02 AB 03
					15 01 00 00 00 00 02 AC C8
					15 01 00 00 00 00 02 AD 03
					15 01 00 00 00 00 02 AE CB
					15 01 00 00 00 00 02 AF 00
					15 01 00 00 00 00 02 B0 16
					15 01 00 00 00 00 02 B1 00
					15 01 00 00 00 00 02 B2 2D
					15 01 00 00 00 00 02 B3 00
					15 01 00 00 00 00 02 B4 54
					15 01 00 00 00 00 02 B5 00
					15 01 00 00 00 00 02 B6 70
					15 01 00 00 00 00 02 B7 00
					15 01 00 00 00 00 02 B8 87
					15 01 00 00 00 00 02 B9 00
					15 01 00 00 00 00 02 BA 9A
					15 01 00 00 00 00 02 BB 00
					15 01 00 00 00 00 02 BC AB
					15 01 00 00 00 00 02 BD 00
					15 01 00 00 00 00 02 BE BA
					15 01 00 00 00 00 02 BF 00
					15 01 00 00 00 00 02 C0 C8
					15 01 00 00 00 00 02 C1 00
					15 01 00 00 00 00 02 C2 F6
					15 01 00 00 00 00 02 C3 01
					15 01 00 00 00 00 02 C4 1A
					15 01 00 00 00 00 02 C5 01
					15 01 00 00 00 00 02 C6 53
					15 01 00 00 00 00 02 C7 01
					15 01 00 00 00 00 02 C8 80
					15 01 00 00 00 00 02 C9 01
					15 01 00 00 00 00 02 CA C7
					15 01 00 00 00 00 02 CB 02
					15 01 00 00 00 00 02 CC 01
					15 01 00 00 00 00 02 CD 02
					15 01 00 00 00 00 02 CE 02
					15 01 00 00 00 00 02 CF 02
					15 01 00 00 00 00 02 D0 39
					15 01 00 00 00 00 02 D1 02
					15 01 00 00 00 00 02 D2 7D
					15 01 00 00 00 00 02 D3 02
					15 01 00 00 00 00 02 D4 AB
					15 01 00 00 00 00 02 D5 02
					15 01 00 00 00 00 02 D6 E8
					15 01 00 00 00 00 02 D7 03
					15 01 00 00 00 00 02 D8 12
					15 01 00 00 00 00 02 D9 03
					15 01 00 00 00 00 02 DA 49
					15 01 00 00 00 00 02 DB 03
					15 01 00 00 00 00 02 DC 5C
					15 01 00 00 00 00 02 DD 03
					15 01 00 00 00 00 02 DE 72
					15 01 00 00 00 00 02 DF 03
					15 01 00 00 00 00 02 E0 83
					15 01 00 00 00 00 02 E1 03
					15 01 00 00 00 00 02 E2 97
					15 01 00 00 00 00 02 E3 03
					15 01 00 00 00 00 02 E4 A4
					15 01 00 00 00 00 02 E5 03
					15 01 00 00 00 00 02 E6 B6
					15 01 00 00 00 00 02 E7 03
					15 01 00 00 00 00 02 E8 C8
					15 01 00 00 00 00 02 E9 03
					15 01 00 00 00 00 02 EA CB
					15 01 00 00 00 00 02 FF 01
					15 01 00 00 00 00 02 15 0F
					15 01 00 00 00 00 02 16 0F
					15 01 00 00 00 00 02 1B 1B
					15 01 00 00 00 00 02 1C F7
					15 01 00 00 00 00 02 66 01
					15 01 00 00 00 00 02 FB 01
					15 01 00 00 00 00 02 FF 05
					15 01 00 00 00 00 02 54 75
					15 01 00 00 00 00 02 A6 04
					15 01 00 00 00 00 02 FB 01
					15 01 00 00 00 00 02 FF FF
					15 01 00 00 00 00 02 4F 03
					15 01 00 00 00 00 02 FB 01
					15 01 00 00 00 00 02 FF 00
					15 01 00 00 00 00 02 FF 00
					15 01 00 00 00 00 02 35 01
					15 01 00 00 00 00 02 D3 08
					15 01 00 00 0A 00 02 D4 06
					05 01 00 00 00 00 01 11];
			qcom,panel-on-cmds = [05 01 00 00 28 00 01 29];
			qcom,on-cmds-dsi-state = "DSI_LP_MODE";
			qcom,panel-off-cmds = [05 01 00 00 14 00 01 28
					05 01 00 00 64 00 01 10];
			qcom,off-cmds-dsi-state = "DSI_HS_MODE";
			somc,driver-ic = <1>;
			somc,disp-on-in-hs = <1>;
			somc,panel-detect = <1>;
			somc,wait-time-before-on-cmd = <80>;
		};

		novatek_auo_1080p_panel {
			label = "novatek auo 1080p video mode dsi panel";
			somc,panel-id = [12 70 61 56];
			qcom,mdss-pan-res = <1080 1920>;
			somc,mdss-phy-size-mm = <80 143>;
			qcom,mdss-pan-bpp = <24>;
			qcom,mdss-pan-dest = "display_1";
			qcom,mdss-pan-porch-values = <56 20 136 6 2 6>;
			qcom,mdss-pan-dsi-mode = <0>;
			qcom,mdss-pan-dsi-h-pulse-mode = <1>;
			qcom,mdss-pan-dsi-h-power-stop = <0 0 0>;
			qcom,mdss-pan-dsi-bllp-power-stop = <1 1>;
			qcom,mdss-pan-dsi-traffic-mode = <1>;
			qcom,mdss-pan-dsi-dst-format = <3>;
			qcom,mdss-pan-dsi-vc = <0>;
			qcom,mdss-pan-dsi-rgb-swap = <0>;
			qcom,mdss-pan-dsi-data-lanes = <1 1 1 1>;
			qcom,mdss-pan-dsi-dlane-swap = <0>;
			qcom,mdss-pan-dsi-t-clk = <0x37 0x1E>;
			qcom,mdss-pan-dsi-stream = <0>;
			qcom,mdss-pan-dsi-mdp-tr = <0x0>;
			qcom,mdss-pan-dsi-dma-tr = <0x04>;
			qcom,mdss-pan-dsi-frame-rate = <60>;
			qcom,panel-phy-regulatorSettings = [07 09 03 00  /* Regualotor settings */
							    20 00 01];
			qcom,panel-phy-timingSettings = [DA 46 39 00 5F 56
							    3C 48 5D 03 04 00];
			qcom,panel-phy-strengthCtrl = [ff 06];
			qcom,panel-phy-bistCtrl = [00 00 b1 ff           /* BIST Ctrl settings */
						   00 00];
			qcom,panel-phy-laneConfig = [00 02 ef 00 00 00 00 01 ff /* lane0 config */
						00 02 ef 00 00 00 00 01 ff /* lane1 config */
						00 02 ef 00 00 00 00 01 ff /* lane2 config */
						00 02 ef 00 00 00 00 01 ff /* lane3 config */
						00 02 45 00 00 00 00 01 97]; /* Clk ln config */

			somc,panel-cabc-early-on-cmds = [15 01 00 00 00 00 02 FF 04
						15 01 00 00 00 00 02 08 05
						15 01 00 00 00 00 02 2A 84
						15 01 00 00 00 00 02 29 99
						15 01 00 00 00 00 02 28 99
						15 01 00 00 00 00 02 27 99
						15 01 00 00 00 00 02 26 AA
						15 01 00 00 00 00 02 25 BB
						15 01 00 00 00 00 02 24 CC
						15 01 00 00 00 00 02 23 DD
						15 01 00 00 00 00 02 22 EE
						15 01 00 00 00 00 02 21 FF
						15 01 00 00 00 00 02 33 0C
						15 01 00 00 00 00 02 FB 01
						15 01 00 00 00 00 02 FF 00
						15 01 00 00 00 00 02 51 FF
						15 01 00 00 00 00 02 53 2C
						15 01 00 00 00 00 02 55 03];
			somc,panel-cabc-late-off-cmds = [15 01 00 00 00 00 02 51 00
						15 01 00 00 00 00 02 53 00
						15 01 00 00 00 00 02 55 00];
			somc,cabc-enabled = <1>;
			somc,panel-init-cmds = [15 01 00 00 00 00 02 FF 01
					15 01 00 00 00 00 02 FB 01
					15 01 00 00 00 00 02 75 00
					15 01 00 00 00 00 02 76 16
					15 01 00 00 00 00 02 77 00
					15 01 00 00 00 00 02 78 2D
					15 01 00 00 00 00 02 79 00
					15 01 00 00 00 00 02 7A 54
					15 01 00 00 00 00 02 7B 00
					15 01 00 00 00 00 02 7C 70
					15 01 00 00 00 00 02 7D 00
					15 01 00 00 00 00 02 7E 87
					15 01 00 00 00 00 02 7F 00
					15 01 00 00 00 00 02 80 9A
					15 01 00 00 00 00 02 81 00
					15 01 00 00 00 00 02 82 AB
					15 01 00 00 00 00 02 83 00
					15 01 00 00 00 00 02 84 BA
					15 01 00 00 00 00 02 85 00
					15 01 00 00 00 00 02 86 C8
					15 01 00 00 00 00 02 87 00
					15 01 00 00 00 00 02 88 F6
					15 01 00 00 00 00 02 89 01
					15 01 00 00 00 00 02 8A 1A
					15 01 00 00 00 00 02 8B 01
					15 01 00 00 00 00 02 8C 53
					15 01 00 00 00 00 02 8D 01
					15 01 00 00 00 00 02 8E 80
					15 01 00 00 00 00 02 8F 01
					15 01 00 00 00 00 02 90 C7
					15 01 00 00 00 00 02 91 02
					15 01 00 00 00 00 02 92 01
					15 01 00 00 00 00 02 93 02
					15 01 00 00 00 00 02 94 02
					15 01 00 00 00 00 02 95 02
					15 01 00 00 00 00 02 96 39
					15 01 00 00 00 00 02 97 02
					15 01 00 00 00 00 02 98 7D
					15 01 00 00 00 00 02 99 02
					15 01 00 00 00 00 02 9A AB
					15 01 00 00 00 00 02 9B 02
					15 01 00 00 00 00 02 9C E8
					15 01 00 00 00 00 02 9D 03
					15 01 00 00 00 00 02 9E 12
					15 01 00 00 00 00 02 9F 03
					15 01 00 00 00 00 02 A0 49
					15 01 00 00 00 00 02 A2 03
					15 01 00 00 00 00 02 A3 5C
					15 01 00 00 00 00 02 A4 03
					15 01 00 00 00 00 02 A5 72
					15 01 00 00 00 00 02 A6 03
					15 01 00 00 00 00 02 A7 83
					15 01 00 00 00 00 02 A9 03
					15 01 00 00 00 00 02 AA 97
					15 01 00 00 00 00 02 AB 03
					15 01 00 00 00 00 02 AC A4
					15 01 00 00 00 00 02 AD 03
					15 01 00 00 00 00 02 AE B6
					15 01 00 00 00 00 02 AF 03
					15 01 00 00 00 00 02 B0 C8
					15 01 00 00 00 00 02 B1 03
					15 01 00 00 00 00 02 B2 CB
					15 01 00 00 00 00 02 B3 00
					15 01 00 00 00 00 02 B4 16
					15 01 00 00 00 00 02 B5 00
					15 01 00 00 00 00 02 B6 2D
					15 01 00 00 00 00 02 B7 00
					15 01 00 00 00 00 02 B8 54
					15 01 00 00 00 00 02 B9 00
					15 01 00 00 00 00 02 BA 70
					15 01 00 00 00 00 02 BB 00
					15 01 00 00 00 00 02 BC 87
					15 01 00 00 00 00 02 BD 00
					15 01 00 00 00 00 02 BE 9A
					15 01 00 00 00 00 02 BF 00
					15 01 00 00 00 00 02 C0 AB
					15 01 00 00 00 00 02 C1 00
					15 01 00 00 00 00 02 C2 BA
					15 01 00 00 00 00 02 C3 00
					15 01 00 00 00 00 02 C4 C8
					15 01 00 00 00 00 02 C5 00
					15 01 00 00 00 00 02 C6 F6
					15 01 00 00 00 00 02 C7 01
					15 01 00 00 00 00 02 C8 1A
					15 01 00 00 00 00 02 C9 01
					15 01 00 00 00 00 02 CA 53
					15 01 00 00 00 00 02 CB 01
					15 01 00 00 00 00 02 CC 80
					15 01 00 00 00 00 02 CD 01
					15 01 00 00 00 00 02 CE C7
					15 01 00 00 00 00 02 CF 02
					15 01 00 00 00 00 02 D0 01
					15 01 00 00 00 00 02 D1 02
					15 01 00 00 00 00 02 D2 02
					15 01 00 00 00 00 02 D3 02
					15 01 00 00 00 00 02 D4 39
					15 01 00 00 00 00 02 D5 02
					15 01 00 00 00 00 02 D6 7D
					15 01 00 00 00 00 02 D7 02
					15 01 00 00 00 00 02 D8 AB
					15 01 00 00 00 00 02 D9 02
					15 01 00 00 00 00 02 DA E8
					15 01 00 00 00 00 02 DB 03
					15 01 00 00 00 00 02 DC 12
					15 01 00 00 00 00 02 DD 03
					15 01 00 00 00 00 02 DE 49
					15 01 00 00 00 00 02 DF 03
					15 01 00 00 00 00 02 E0 5C
					15 01 00 00 00 00 02 E1 03
					15 01 00 00 00 00 02 E2 72
					15 01 00 00 00 00 02 E3 03
					15 01 00 00 00 00 02 E4 83
					15 01 00 00 00 00 02 E5 03
					15 01 00 00 00 00 02 E6 97
					15 01 00 00 00 00 02 E7 03
					15 01 00 00 00 00 02 E8 A4
					15 01 00 00 00 00 02 E9 03
					15 01 00 00 00 00 02 EA B6
					15 01 00 00 00 00 02 EB 03
					15 01 00 00 00 00 02 EC C8
					15 01 00 00 00 00 02 ED 03
					15 01 00 00 00 00 02 EE CB
					15 01 00 00 00 00 02 EF 00
					15 01 00 00 00 00 02 F0 16
					15 01 00 00 00 00 02 F1 00
					15 01 00 00 00 00 02 F2 2D
					15 01 00 00 00 00 02 F3 00
					15 01 00 00 00 00 02 F4 54
					15 01 00 00 00 00 02 F5 00
					15 01 00 00 00 00 02 F6 70
					15 01 00 00 00 00 02 F7 00
					15 01 00 00 00 00 02 F8 87
					15 01 00 00 00 00 02 F9 00
					15 01 00 00 00 00 02 FA 9A
					15 01 00 00 00 00 02 FF 02
					15 01 00 00 00 00 02 FB 01
					15 01 00 00 00 00 02 00 00
					15 01 00 00 00 00 02 01 AB
					15 01 00 00 00 00 02 02 00
					15 01 00 00 00 00 02 03 BA
					15 01 00 00 00 00 02 04 00
					15 01 00 00 00 00 02 05 C8
					15 01 00 00 00 00 02 06 00
					15 01 00 00 00 00 02 07 F6
					15 01 00 00 00 00 02 08 01
					15 01 00 00 00 00 02 09 1A
					15 01 00 00 00 00 02 0A 01
					15 01 00 00 00 00 02 0B 53
					15 01 00 00 00 00 02 0C 01
					15 01 00 00 00 00 02 0D 80
					15 01 00 00 00 00 02 0E 01
					15 01 00 00 00 00 02 0F C7
					15 01 00 00 00 00 02 10 02
					15 01 00 00 00 00 02 11 01
					15 01 00 00 00 00 02 12 02
					15 01 00 00 00 00 02 13 02
					15 01 00 00 00 00 02 14 02
					15 01 00 00 00 00 02 15 39
					15 01 00 00 00 00 02 16 02
					15 01 00 00 00 00 02 17 7D
					15 01 00 00 00 00 02 18 02
					15 01 00 00 00 00 02 19 AB
					15 01 00 00 00 00 02 1A 02
					15 01 00 00 00 00 02 1B E8
					15 01 00 00 00 00 02 1C 03
					15 01 00 00 00 00 02 1D 12
					15 01 00 00 00 00 02 1E 03
					15 01 00 00 00 00 02 1F 49
					15 01 00 00 00 00 02 20 03
					15 01 00 00 00 00 02 21 5C
					15 01 00 00 00 00 02 22 03
					15 01 00 00 00 00 02 23 72
					15 01 00 00 00 00 02 24 03
					15 01 00 00 00 00 02 25 83
					15 01 00 00 00 00 02 26 03
					15 01 00 00 00 00 02 27 97
					15 01 00 00 00 00 02 28 03
					15 01 00 00 00 00 02 29 A4
					15 01 00 00 00 00 02 2A 03
					15 01 00 00 00 00 02 2B B6
					15 01 00 00 00 00 02 2D 03
					15 01 00 00 00 00 02 2F C8
					15 01 00 00 00 00 02 30 03
					15 01 00 00 00 00 02 31 CB
					15 01 00 00 00 00 02 32 00
					15 01 00 00 00 00 02 33 16
					15 01 00 00 00 00 02 34 00
					15 01 00 00 00 00 02 35 2D
					15 01 00 00 00 00 02 36 00
					15 01 00 00 00 00 02 37 54
					15 01 00 00 00 00 02 38 00
					15 01 00 00 00 00 02 39 70
					15 01 00 00 00 00 02 3A 00
					15 01 00 00 00 00 02 3B 87
					15 01 00 00 00 00 02 3D 00
					15 01 00 00 00 00 02 3F 9A
					15 01 00 00 00 00 02 40 00
					15 01 00 00 00 00 02 41 AB
					15 01 00 00 00 00 02 42 00
					15 01 00 00 00 00 02 43 BA
					15 01 00 00 00 00 02 44 00
					15 01 00 00 00 00 02 45 C8
					15 01 00 00 00 00 02 46 00
					15 01 00 00 00 00 02 47 F6
					15 01 00 00 00 00 02 48 01
					15 01 00 00 00 00 02 49 1A
					15 01 00 00 00 00 02 4A 01
					15 01 00 00 00 00 02 4B 53
					15 01 00 00 00 00 02 4C 01
					15 01 00 00 00 00 02 4D 80
					15 01 00 00 00 00 02 4E 01
					15 01 00 00 00 00 02 4F C7
					15 01 00 00 00 00 02 50 02
					15 01 00 00 00 00 02 51 01
					15 01 00 00 00 00 02 52 02
					15 01 00 00 00 00 02 53 02
					15 01 00 00 00 00 02 54 02
					15 01 00 00 00 00 02 55 39
					15 01 00 00 00 00 02 56 02
					15 01 00 00 00 00 02 58 7D
					15 01 00 00 00 00 02 59 02
					15 01 00 00 00 00 02 5A AB
					15 01 00 00 00 00 02 5B 02
					15 01 00 00 00 00 02 5C E8
					15 01 00 00 00 00 02 5D 03
					15 01 00 00 00 00 02 5E 12
					15 01 00 00 00 00 02 5F 03
					15 01 00 00 00 00 02 60 49
					15 01 00 00 00 00 02 61 03
					15 01 00 00 00 00 02 62 5C
					15 01 00 00 00 00 02 63 03
					15 01 00 00 00 00 02 64 72
					15 01 00 00 00 00 02 65 03
					15 01 00 00 00 00 02 66 83
					15 01 00 00 00 00 02 67 03
					15 01 00 00 00 00 02 68 97
					15 01 00 00 00 00 02 69 03
					15 01 00 00 00 00 02 6A A4
					15 01 00 00 00 00 02 6B 03
					15 01 00 00 00 00 02 6C B6
					15 01 00 00 00 00 02 6D 03
					15 01 00 00 00 00 02 6E C8
					15 01 00 00 00 00 02 6F 03
					15 01 00 00 00 00 02 70 CB
					15 01 00 00 00 00 02 71 00
					15 01 00 00 00 00 02 72 16
					15 01 00 00 00 00 02 73 00
					15 01 00 00 00 00 02 74 2D
					15 01 00 00 00 00 02 75 00
					15 01 00 00 00 00 02 76 54
					15 01 00 00 00 00 02 77 00
					15 01 00 00 00 00 02 78 70
					15 01 00 00 00 00 02 79 00
					15 01 00 00 00 00 02 7A 87
					15 01 00 00 00 00 02 7B 00
					15 01 00 00 00 00 02 7C 9A
					15 01 00 00 00 00 02 7D 00
					15 01 00 00 00 00 02 7E AB
					15 01 00 00 00 00 02 7F 00
					15 01 00 00 00 00 02 80 BA
					15 01 00 00 00 00 02 81 00
					15 01 00 00 00 00 02 82 C8
					15 01 00 00 00 00 02 83 00
					15 01 00 00 00 00 02 84 F6
					15 01 00 00 00 00 02 85 01
					15 01 00 00 00 00 02 86 1A
					15 01 00 00 00 00 02 87 01
					15 01 00 00 00 00 02 88 53
					15 01 00 00 00 00 02 89 01
					15 01 00 00 00 00 02 8A 80
					15 01 00 00 00 00 02 8B 01
					15 01 00 00 00 00 02 8C C7
					15 01 00 00 00 00 02 8D 02
					15 01 00 00 00 00 02 8E 01
					15 01 00 00 00 00 02 8F 02
					15 01 00 00 00 00 02 90 02
					15 01 00 00 00 00 02 91 02
					15 01 00 00 00 00 02 92 39
					15 01 00 00 00 00 02 93 02
					15 01 00 00 00 00 02 94 7D
					15 01 00 00 00 00 02 95 02
					15 01 00 00 00 00 02 96 AB
					15 01 00 00 00 00 02 97 02
					15 01 00 00 00 00 02 98 E8
					15 01 00 00 00 00 02 99 03
					15 01 00 00 00 00 02 9A 12
					15 01 00 00 00 00 02 9B 03
					15 01 00 00 00 00 02 9C 49
					15 01 00 00 00 00 02 9D 03
					15 01 00 00 00 00 02 9E 5C
					15 01 00 00 00 00 02 9F 03
					15 01 00 00 00 00 02 A0 72
					15 01 00 00 00 00 02 A2 03
					15 01 00 00 00 00 02 A3 83
					15 01 00 00 00 00 02 A4 03
					15 01 00 00 00 00 02 A5 97
					15 01 00 00 00 00 02 A6 03
					15 01 00 00 00 00 02 A7 A4
					15 01 00 00 00 00 02 A9 03
					15 01 00 00 00 00 02 AA B6
					15 01 00 00 00 00 02 AB 03
					15 01 00 00 00 00 02 AC C8
					15 01 00 00 00 00 02 AD 03
					15 01 00 00 00 00 02 AE CB
					15 01 00 00 00 00 02 AF 00
					15 01 00 00 00 00 02 B0 16
					15 01 00 00 00 00 02 B1 00
					15 01 00 00 00 00 02 B2 2D
					15 01 00 00 00 00 02 B3 00
					15 01 00 00 00 00 02 B4 54
					15 01 00 00 00 00 02 B5 00
					15 01 00 00 00 00 02 B6 70
					15 01 00 00 00 00 02 B7 00
					15 01 00 00 00 00 02 B8 87
					15 01 00 00 00 00 02 B9 00
					15 01 00 00 00 00 02 BA 9A
					15 01 00 00 00 00 02 BB 00
					15 01 00 00 00 00 02 BC AB
					15 01 00 00 00 00 02 BD 00
					15 01 00 00 00 00 02 BE BA
					15 01 00 00 00 00 02 BF 00
					15 01 00 00 00 00 02 C0 C8
					15 01 00 00 00 00 02 C1 00
					15 01 00 00 00 00 02 C2 F6
					15 01 00 00 00 00 02 C3 01
					15 01 00 00 00 00 02 C4 1A
					15 01 00 00 00 00 02 C5 01
					15 01 00 00 00 00 02 C6 53
					15 01 00 00 00 00 02 C7 01
					15 01 00 00 00 00 02 C8 80
					15 01 00 00 00 00 02 C9 01
					15 01 00 00 00 00 02 CA C7
					15 01 00 00 00 00 02 CB 02
					15 01 00 00 00 00 02 CC 01
					15 01 00 00 00 00 02 CD 02
					15 01 00 00 00 00 02 CE 02
					15 01 00 00 00 00 02 CF 02
					15 01 00 00 00 00 02 D0 39
					15 01 00 00 00 00 02 D1 02
					15 01 00 00 00 00 02 D2 7D
					15 01 00 00 00 00 02 D3 02
					15 01 00 00 00 00 02 D4 AB
					15 01 00 00 00 00 02 D5 02
					15 01 00 00 00 00 02 D6 E8
					15 01 00 00 00 00 02 D7 03
					15 01 00 00 00 00 02 D8 12
					15 01 00 00 00 00 02 D9 03
					15 01 00 00 00 00 02 DA 49
					15 01 00 00 00 00 02 DB 03
					15 01 00 00 00 00 02 DC 5C
					15 01 00 00 00 00 02 DD 03
					15 01 00 00 00 00 02 DE 72
					15 01 00 00 00 00 02 DF 03
					15 01 00 00 00 00 02 E0 83
					15 01 00 00 00 00 02 E1 03
					15 01 00 00 00 00 02 E2 97
					15 01 00 00 00 00 02 E3 03
					15 01 00 00 00 00 02 E4 A4
					15 01 00 00 00 00 02 E5 03
					15 01 00 00 00 00 02 E6 B6
					15 01 00 00 00 00 02 E7 03
					15 01 00 00 00 00 02 E8 C8
					15 01 00 00 00 00 02 E9 03
					15 01 00 00 00 00 02 EA CB
					15 01 00 00 00 00 02 FF 01
					15 01 00 00 00 00 02 15 0F
					15 01 00 00 00 00 02 16 0F
					15 01 00 00 00 00 02 1B 1B
					15 01 00 00 00 00 02 1C F7
					15 01 00 00 00 00 02 66 01
					15 01 00 00 00 00 02 FB 01
					15 01 00 00 00 00 02 FF 05
					15 01 00 00 00 00 02 54 75
					15 01 00 00 00 00 02 A6 04
					15 01 00 00 00 00 02 FB 01
					15 01 00 00 00 00 02 FF FF
					15 01 00 00 00 00 02 4F 03
					15 01 00 00 00 00 02 FB 01
					15 01 00 00 00 00 02 FF 00
					15 01 00 00 00 00 02 FF 00
					15 01 00 00 00 00 02 35 01
					15 01 00 00 00 00 02 D3 08
					15 01 00 00 0A 00 02 D4 06
					05 01 00 00 00 00 01 11];
			qcom,panel-on-cmds = [05 01 00 00 28 00 01 29];
			qcom,on-cmds-dsi-state = "DSI_LP_MODE";
			qcom,panel-off-cmds = [05 01 00 00 14 00 01 28
					05 01 00 00 64 00 01 10];
			qcom,off-cmds-dsi-state = "DSI_HS_MODE";
			somc,driver-ic = <1>;
			somc,disp-on-in-hs = <1>;
			somc,wait-time-before-on-cmd = <80>;

			somc,panel-uv-cmds = [04 01 00 00 00 00 01 04];
			somc,panel-pcc-table = <0x07c00 0x05f80 0x07380	/* CLR01_GRN */
					0x05100 0x06600 0x07380		/* CLR02_YEL */
					0x07d80 0x05f80 0x06300		/* CLR03_LB */
					0x04e00 0x06600 0x06100		/* CLR04_ORG */
					0x07d00 0x05f00 0x05680		/* CLR05_BLE */
					0x07d80 0x08000 0x06f80		/* CLR06_PUR */
					0x04d00 0x06600 0x05280>;	/* CLR07_RED */
			somc,panel-pcc-sub-table = <0x06800 0x06f80 0x08000 /* Area01 (R G B) */
					0x06500 0x07100 0x08000
					0x07600 0x07400 0x08000
					0x07480 0x07580 0x08000
					0x07280 0x07500 0x08000
					0x06d80 0x07500 0x08000
					0x06780 0x07300 0x08000
					0x07a00 0x07680 0x08000
					0x07900 0x07800 0x08000
					0x07180 0x07800 0x08000
					0x06f00 0x07880 0x08000
					0x06c00 0x07800 0x08000
					0x07d80 0x07980 0x08000
					0x07b80 0x07b00 0x08000
					0x07600 0x07d00 0x08000
					0x07180 0x07b00 0x08000
					0x07000 0x07d00 0x08000
					0x08000 0x07980 0x07d00
					0x07f00 0x07b00 0x07d80
					0x07c00 0x07c00 0x07c80
					0x07100 0x07b00 0x07d00
					0x07280 0x07d00 0x07e80
					0x07000 0x07d00 0x07e80
					0x08000 0x07800 0x07900
					0x08000 0x07c00 0x07c00
					0x07a80 0x08000 0x07e80
					0x07680 0x08000 0x07d80
					0x07300 0x08000 0x07f00
					0x08000 0x07800 0x07580
					0x08000 0x07b00 0x07780
					0x08000 0x08000 0x07c80
					0x07900 0x08000 0x07980
					0x08000 0x07880 0x07480
					0x08000 0x07c00 0x07600
					0x07d80 0x08000 0x07880
					0x07300 0x08000 0x07780
					0x08000 0x07400 0x07c80
					0x07880 0x06e00 0x08000
					0x06b80 0x06b00 0x07e00
					0x06080 0x05f80 0x07780
					0x05880 0x06500 0x07c80
					0x05500 0x06600 0x05e80>;
		};
	};
};
